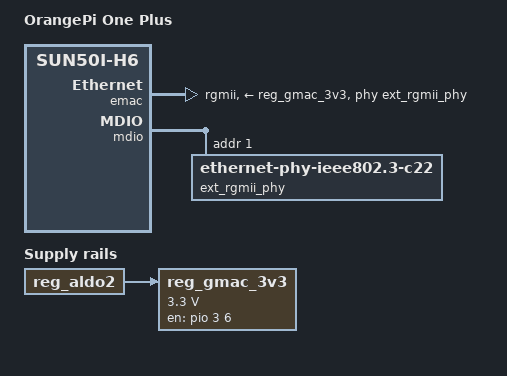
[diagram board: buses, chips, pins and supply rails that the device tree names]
// SPDX-License-Identifier: (GPL-2.0+ OR MIT)
// Copyright (C) 2018 Amarula Solutions
// Author: Jagan Teki <jagan@amarulasolutions.com>

#include "sun50i-h6-orangepi.dtsi"

/ {
	model = "OrangePi One Plus";
	compatible = "xunlong,orangepi-one-plus", "allwinner,sun50i-h6";

	aliases {
		ethernet0 = &emac;
	};

	reg_gmac_3v3: gmac-3v3 {
		compatible = "regulator-fixed";
		regulator-name = "vcc-gmac-3v3";
		regulator-min-microvolt = <3300000>;
		regulator-max-microvolt = <3300000>;
		startup-delay-us = <100000>;
		enable-active-high;
		gpio = <&pio 3 6 GPIO_ACTIVE_HIGH>; /* PD6 */
		vin-supply = <&reg_aldo2>;
	};
};

&emac {
	pinctrl-names = "default";
	pinctrl-0 = <&ext_rgmii_pins>;
	phy-mode = "rgmii";
	phy-handle = <&ext_rgmii_phy>;
	phy-supply = <&reg_gmac_3v3>;
	allwinner,rx-delay-ps = <200>;
	allwinner,tx-delay-ps = <200>;
	status = "okay";
};

&mdio {
	ext_rgmii_phy: ethernet-phy@1 {
		compatible = "ethernet-phy-ieee802.3-c22";
		reg = <1>;
	};
};
